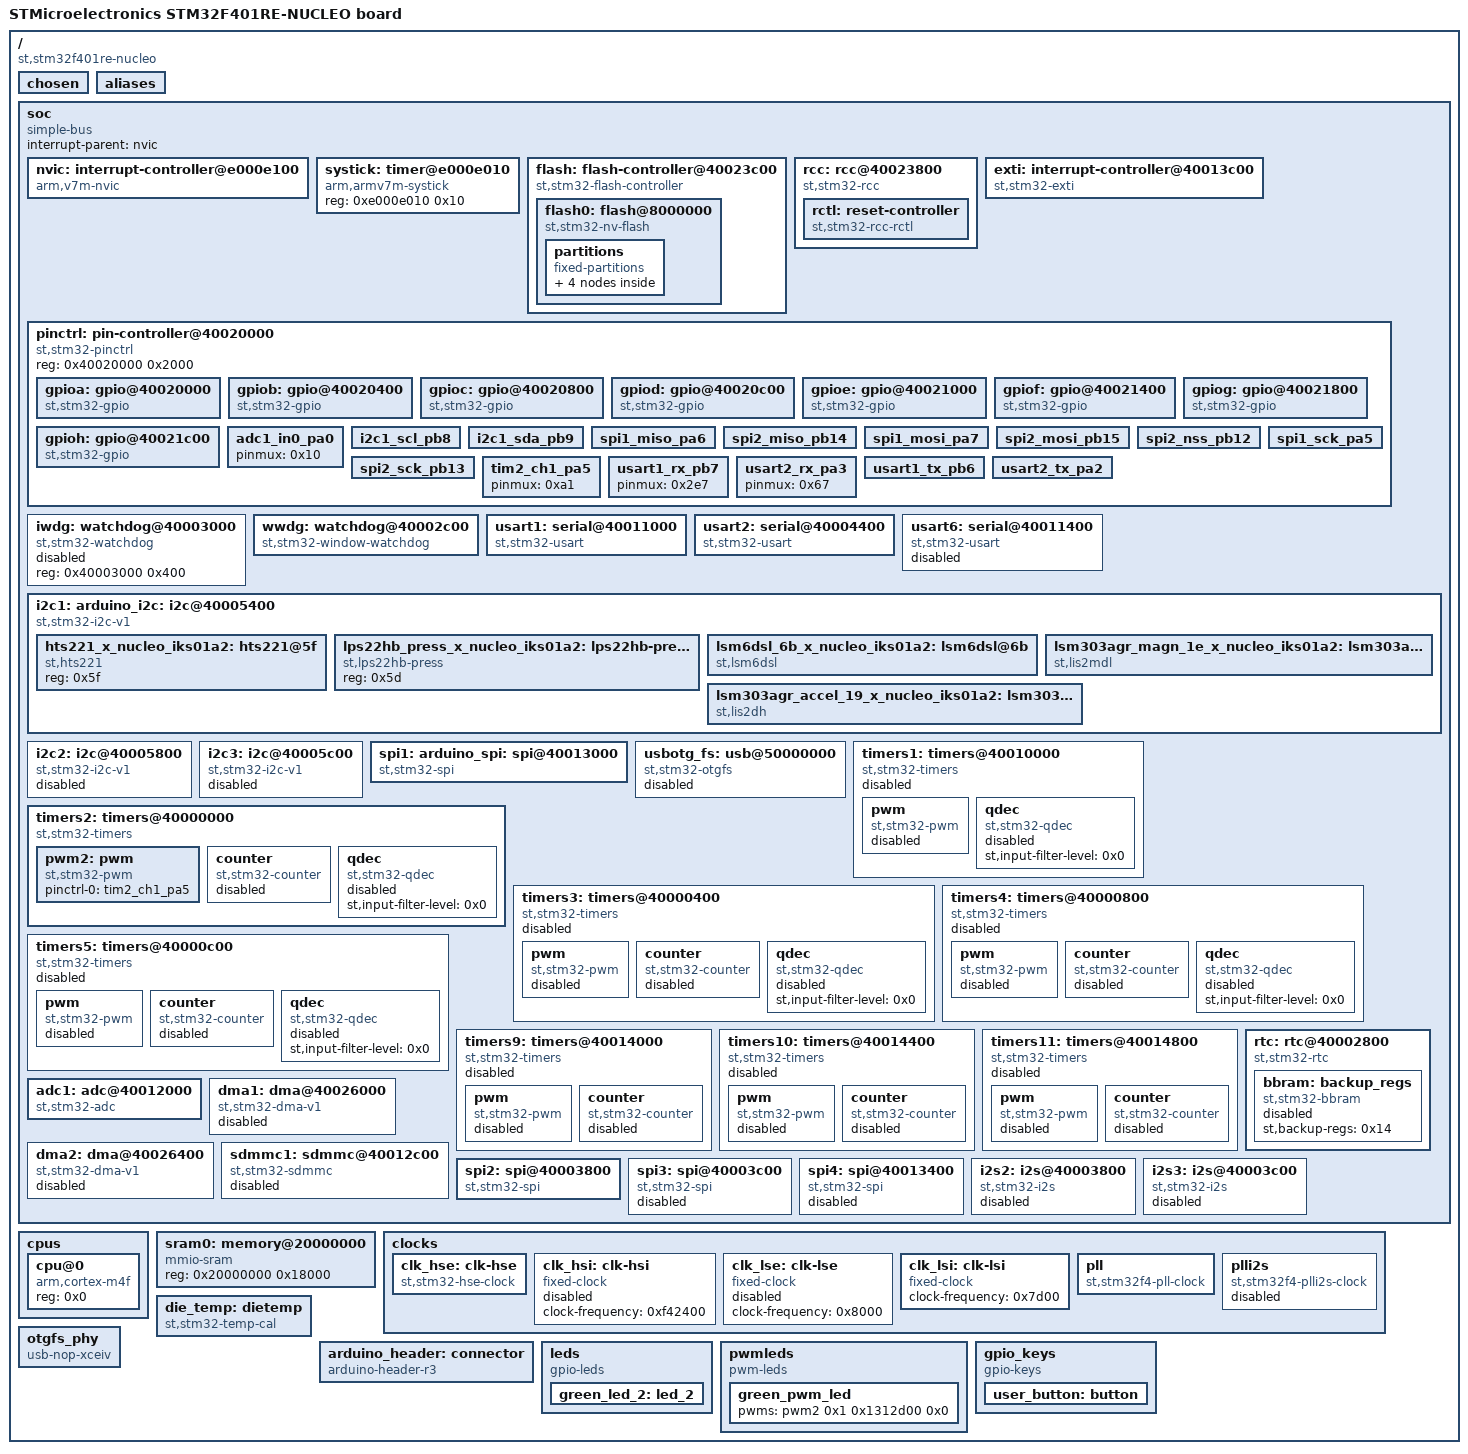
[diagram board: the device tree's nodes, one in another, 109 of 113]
/dts-v1/;

/ {
	#address-cells = < 0x1 >;
	#size-cells = < 0x1 >;
	model = "STMicroelectronics STM32F401RE-NUCLEO board";
	compatible = "st,stm32f401re-nucleo";
	chosen {
		zephyr,flash-controller = &flash;
		zephyr,console = &usart2;
		zephyr,shell-uart = &usart2;
		zephyr,sram = &sram0;
		zephyr,flash = &flash0;
		zephyr,code-partition = &slot0_partition;
	};
	aliases {
		led0 = &green_led_2;
		sw0 = &user_button;
		pwm-led0 = &green_pwm_led;
		watchdog0 = &wwdg;
		magn0 = &lsm303agr_magn_1e_x_nucleo_iks01a2;
		accel0 = &lsm303agr_accel_19_x_nucleo_iks01a2;
		accel1 = &lsm6dsl_6b_x_nucleo_iks01a2;
	};
	soc {
		#address-cells = < 0x1 >;
		#size-cells = < 0x1 >;
		compatible = "simple-bus";
		interrupt-parent = < &nvic >;
		ranges;
		nvic: interrupt-controller@e000e100 {
			#address-cells = < 0x1 >;
			compatible = "arm,v7m-nvic";
			reg = < 0xe000e100 0xc00 >;
			interrupt-controller;
			#interrupt-cells = < 0x2 >;
			arm,num-irq-priority-bits = < 0x4 >;
			phandle = < 0x1 >;
		};
		systick: timer@e000e010 {
			compatible = "arm,armv7m-systick";
			reg = < 0xe000e010 0x10 >;
		};
		flash: flash-controller@40023c00 {
			compatible = "st,stm32-flash-controller", "st,stm32f4-flash-controller";
			reg = < 0x40023c00 0x400 >;
			interrupts = < 0x4 0x0 >;
			#address-cells = < 0x1 >;
			#size-cells = < 0x1 >;
			flash0: flash@8000000 {
				compatible = "st,stm32-nv-flash", "soc-nv-flash";
				write-block-size = < 0x1 >;
				max-erase-time = < 0xfa0 >;
				reg = < 0x8000000 0x80000 >;
				partitions {
					compatible = "fixed-partitions";
					#address-cells = < 0x1 >;
					#size-cells = < 0x1 >;
					boot_partition: partition@0 {
						label = "mcuboot";
						reg = < 0x0 0x10000 >;
						read-only;
					};
					slot0_partition: partition@20000 {
						label = "image-0";
						reg = < 0x20000 0x20000 >;
					};
					slot1_partition: partition@40000 {
						label = "image-1";
						reg = < 0x40000 0x20000 >;
					};
					scratch_partition: partition@60000 {
						label = "image-scratch";
						reg = < 0x60000 0x20000 >;
					};
				};
			};
		};
		rcc: rcc@40023800 {
			compatible = "st,stm32-rcc";
			#clock-cells = < 0x2 >;
			reg = < 0x40023800 0x400 >;
			clocks = < &pll >;
			clock-frequency = < 0x501bd00 >;
			ahb-prescaler = < 0x1 >;
			apb1-prescaler = < 0x2 >;
			apb2-prescaler = < 0x1 >;
			phandle = < 0x3 >;
			rctl: reset-controller {
				compatible = "st,stm32-rcc-rctl";
				#reset-cells = < 0x1 >;
				phandle = < 0x4 >;
			};
		};
		exti: interrupt-controller@40013c00 {
			compatible = "st,stm32-exti";
			interrupt-controller;
			#interrupt-cells = < 0x1 >;
			reg = < 0x40013c00 0x400 >;
			num-lines = < 0x10 >;
			interrupts = < 0x6 0x0 >, < 0x7 0x0 >, < 0x8 0x0 >, < 0x9 0x0 >, < 0xa 0x0 >, < 0x17 0x0 >, < 0x28 0x0 >;
			interrupt-names = "line0", "line1", "line2", "line3", "line4", "line5-9", "line10-15";
			line-ranges = < 0x0 0x1 >, < 0x1 0x1 >, < 0x2 0x1 >, < 0x3 0x1 >, < 0x4 0x1 >, < 0x5 0x5 >, < 0xa 0x6 >;
		};
		pinctrl: pin-controller@40020000 {
			compatible = "st,stm32-pinctrl";
			#address-cells = < 0x1 >;
			#size-cells = < 0x1 >;
			reg = < 0x40020000 0x2000 >;
			gpioa: gpio@40020000 {
				compatible = "st,stm32-gpio";
				gpio-controller;
				#gpio-cells = < 0x2 >;
				reg = < 0x40020000 0x400 >;
				clocks = < &rcc 0x30 0x1 >;
				phandle = < 0x1a >;
			};
			gpiob: gpio@40020400 {
				compatible = "st,stm32-gpio";
				gpio-controller;
				#gpio-cells = < 0x2 >;
				reg = < 0x40020400 0x400 >;
				clocks = < &rcc 0x30 0x2 >;
				phandle = < 0xf >;
			};
			gpioc: gpio@40020800 {
				compatible = "st,stm32-gpio";
				gpio-controller;
				#gpio-cells = < 0x2 >;
				reg = < 0x40020800 0x400 >;
				clocks = < &rcc 0x30 0x4 >;
				phandle = < 0x1b >;
			};
			gpiod: gpio@40020c00 {
				compatible = "st,stm32-gpio";
				gpio-controller;
				#gpio-cells = < 0x2 >;
				reg = < 0x40020c00 0x400 >;
				clocks = < &rcc 0x30 0x8 >;
			};
			gpioe: gpio@40021000 {
				compatible = "st,stm32-gpio";
				gpio-controller;
				#gpio-cells = < 0x2 >;
				reg = < 0x40021000 0x400 >;
				clocks = < &rcc 0x30 0x10 >;
			};
			gpiof: gpio@40021400 {
				compatible = "st,stm32-gpio";
				gpio-controller;
				#gpio-cells = < 0x2 >;
				reg = < 0x40021400 0x400 >;
				clocks = < &rcc 0x30 0x20 >;
			};
			gpiog: gpio@40021800 {
				compatible = "st,stm32-gpio";
				gpio-controller;
				#gpio-cells = < 0x2 >;
				reg = < 0x40021800 0x400 >;
				clocks = < &rcc 0x30 0x40 >;
			};
			gpioh: gpio@40021c00 {
				compatible = "st,stm32-gpio";
				gpio-controller;
				#gpio-cells = < 0x2 >;
				reg = < 0x40021c00 0x400 >;
				clocks = < &rcc 0x30 0x80 >;
			};
			adc1_in0_pa0: adc1_in0_pa0 {
				pinmux = < 0x10 >;
				phandle = < 0x12 >;
			};
			i2c1_scl_pb8: i2c1_scl_pb8 {
				pinmux = < 0x304 >;
				bias-pull-up;
				drive-open-drain;
				phandle = < 0x9 >;
			};
			i2c1_sda_pb9: i2c1_sda_pb9 {
				pinmux = < 0x324 >;
				bias-pull-up;
				drive-open-drain;
				phandle = < 0xa >;
			};
			spi1_miso_pa6: spi1_miso_pa6 {
				pinmux = < 0xc5 >;
				bias-pull-down;
				phandle = < 0xd >;
			};
			spi2_miso_pb14: spi2_miso_pb14 {
				pinmux = < 0x3c5 >;
				bias-pull-down;
				phandle = < 0x15 >;
			};
			spi1_mosi_pa7: spi1_mosi_pa7 {
				pinmux = < 0xe5 >;
				bias-pull-down;
				phandle = < 0xe >;
			};
			spi2_mosi_pb15: spi2_mosi_pb15 {
				pinmux = < 0x3e5 >;
				bias-pull-down;
				phandle = < 0x16 >;
			};
			spi2_nss_pb12: spi2_nss_pb12 {
				pinmux = < 0x385 >;
				bias-pull-up;
				phandle = < 0x13 >;
			};
			spi1_sck_pa5: spi1_sck_pa5 {
				pinmux = < 0xa5 >;
				bias-pull-down;
				slew-rate = "very-high-speed";
				phandle = < 0xc >;
			};
			spi2_sck_pb13: spi2_sck_pb13 {
				pinmux = < 0x3a5 >;
				bias-pull-down;
				slew-rate = "very-high-speed";
				phandle = < 0x14 >;
			};
			tim2_ch1_pa5: tim2_ch1_pa5 {
				pinmux = < 0xa1 >;
				phandle = < 0x11 >;
			};
			usart1_rx_pb7: usart1_rx_pb7 {
				pinmux = < 0x2e7 >;
				phandle = < 0x6 >;
			};
			usart2_rx_pa3: usart2_rx_pa3 {
				pinmux = < 0x67 >;
				phandle = < 0x8 >;
			};
			usart1_tx_pb6: usart1_tx_pb6 {
				pinmux = < 0x2c7 >;
				bias-pull-up;
				phandle = < 0x5 >;
			};
			usart2_tx_pa2: usart2_tx_pa2 {
				pinmux = < 0x47 >;
				bias-pull-up;
				phandle = < 0x7 >;
			};
		};
		iwdg: watchdog@40003000 {
			compatible = "st,stm32-watchdog";
			reg = < 0x40003000 0x400 >;
			status = "disabled";
		};
		wwdg: watchdog@40002c00 {
			compatible = "st,stm32-window-watchdog";
			reg = < 0x40002c00 0x400 >;
			clocks = < &rcc 0x40 0x800 >;
			interrupts = < 0x0 0x7 >;
			status = "okay";
		};
		usart1: serial@40011000 {
			compatible = "st,stm32-usart", "st,stm32-uart";
			reg = < 0x40011000 0x400 >;
			clocks = < &rcc 0x44 0x10 >;
			resets = < &rctl 0x484 >;
			interrupts = < 0x25 0x0 >;
			status = "okay";
			pinctrl-0 = < &usart1_tx_pb6 &usart1_rx_pb7 >;
			pinctrl-names = "default";
			current-speed = < 0x1c200 >;
		};
		usart2: serial@40004400 {
			compatible = "st,stm32-usart", "st,stm32-uart";
			reg = < 0x40004400 0x400 >;
			clocks = < &rcc 0x40 0x20000 >;
			resets = < &rctl 0x411 >;
			interrupts = < 0x26 0x0 >;
			status = "okay";
			pinctrl-0 = < &usart2_tx_pa2 &usart2_rx_pa3 >;
			pinctrl-names = "default";
			current-speed = < 0x1c200 >;
		};
		usart6: serial@40011400 {
			compatible = "st,stm32-usart", "st,stm32-uart";
			reg = < 0x40011400 0x400 >;
			clocks = < &rcc 0x44 0x20 >;
			resets = < &rctl 0x485 >;
			interrupts = < 0x47 0x0 >;
			status = "disabled";
		};
		i2c1: arduino_i2c: i2c@40005400 {
			compatible = "st,stm32-i2c-v1";
			clock-frequency = < 0x61a80 >;
			#address-cells = < 0x1 >;
			#size-cells = < 0x0 >;
			reg = < 0x40005400 0x400 >;
			clocks = < &rcc 0x40 0x200000 >;
			interrupts = < 0x1f 0x0 >, < 0x20 0x0 >;
			interrupt-names = "event", "error";
			status = "okay";
			pinctrl-0 = < &i2c1_scl_pb8 &i2c1_sda_pb9 >;
			pinctrl-names = "default";
			hts221_x_nucleo_iks01a2: hts221@5f {
				compatible = "st,hts221";
				reg = < 0x5f >;
			};
			lps22hb_press_x_nucleo_iks01a2: lps22hb-press@5d {
				compatible = "st,lps22hb-press";
				reg = < 0x5d >;
			};
			lsm6dsl_6b_x_nucleo_iks01a2: lsm6dsl@6b {
				compatible = "st,lsm6dsl";
				reg = < 0x6b >;
				irq-gpios = < &arduino_header 0xa 0x0 >;
			};
			lsm303agr_magn_1e_x_nucleo_iks01a2: lsm303agr-magn@1e {
				compatible = "st,lis2mdl", "st,lsm303agr-magn";
				reg = < 0x1e >;
				irq-gpios = < &arduino_header 0x3 0x0 >;
			};
			lsm303agr_accel_19_x_nucleo_iks01a2: lsm303agr-accel@19 {
				compatible = "st,lis2dh", "st,lsm303agr-accel";
				reg = < 0x19 >;
				irq-gpios = < &arduino_header 0x3 0x0 >;
			};
		};
		i2c2: i2c@40005800 {
			compatible = "st,stm32-i2c-v1";
			clock-frequency = < 0x186a0 >;
			#address-cells = < 0x1 >;
			#size-cells = < 0x0 >;
			reg = < 0x40005800 0x400 >;
			clocks = < &rcc 0x40 0x400000 >;
			interrupts = < 0x21 0x0 >, < 0x22 0x0 >;
			interrupt-names = "event", "error";
			status = "disabled";
		};
		i2c3: i2c@40005c00 {
			compatible = "st,stm32-i2c-v1";
			clock-frequency = < 0x186a0 >;
			#address-cells = < 0x1 >;
			#size-cells = < 0x0 >;
			reg = < 0x40005c00 0x400 >;
			clocks = < &rcc 0x40 0x800000 >;
			interrupts = < 0x48 0x0 >, < 0x49 0x0 >;
			interrupt-names = "event", "error";
			status = "disabled";
		};
		spi1: arduino_spi: spi@40013000 {
			compatible = "st,stm32-spi";
			#address-cells = < 0x1 >;
			#size-cells = < 0x0 >;
			reg = < 0x40013000 0x400 >;
			clocks = < &rcc 0x44 0x1000 >;
			interrupts = < 0x23 0x5 >;
			status = "okay";
			pinctrl-0 = < &spi1_sck_pa5 &spi1_miso_pa6 &spi1_mosi_pa7 >;
			pinctrl-names = "default";
			cs-gpios = < &gpiob 0x6 0x11 >;
		};
		usbotg_fs: usb@50000000 {
			compatible = "st,stm32-otgfs";
			reg = < 0x50000000 0x40000 >;
			interrupts = < 0x43 0x0 >;
			interrupt-names = "otgfs";
			num-bidir-endpoints = < 0x4 >;
			ram-size = < 0x500 >;
			maximum-speed = "full-speed";
			phys = < &otgfs_phy >;
			clocks = < &rcc 0x34 0x80 >, < &rcc 0x2 0xff >;
			status = "disabled";
		};
		timers1: timers@40010000 {
			compatible = "st,stm32-timers";
			reg = < 0x40010000 0x400 >;
			clocks = < &rcc 0x44 0x1 >;
			resets = < &rctl 0x480 >;
			interrupts = < 0x18 0x0 >, < 0x19 0x0 >, < 0x1a 0x0 >, < 0x1b 0x0 >;
			interrupt-names = "brk", "up", "trgcom", "cc";
			st,prescaler = < 0x0 >;
			status = "disabled";
			pwm {
				compatible = "st,stm32-pwm";
				status = "disabled";
				#pwm-cells = < 0x3 >;
			};
			qdec {
				compatible = "st,stm32-qdec";
				status = "disabled";
				st,input-filter-level = < 0x0 >;
			};
		};
		timers2: timers@40000000 {
			compatible = "st,stm32-timers";
			reg = < 0x40000000 0x400 >;
			clocks = < &rcc 0x40 0x1 >;
			resets = < &rctl 0x400 >;
			interrupts = < 0x1c 0x0 >;
			interrupt-names = "global";
			st,prescaler = < 0x0 >;
			status = "okay";
			pwm2: pwm {
				compatible = "st,stm32-pwm";
				status = "okay";
				#pwm-cells = < 0x3 >;
				pinctrl-0 = < &tim2_ch1_pa5 >;
				pinctrl-names = "default";
				phandle = < 0x1c >;
			};
			counter {
				compatible = "st,stm32-counter";
				status = "disabled";
			};
			qdec {
				compatible = "st,stm32-qdec";
				status = "disabled";
				st,input-filter-level = < 0x0 >;
			};
		};
		timers3: timers@40000400 {
			compatible = "st,stm32-timers";
			reg = < 0x40000400 0x400 >;
			clocks = < &rcc 0x40 0x2 >;
			resets = < &rctl 0x401 >;
			interrupts = < 0x1d 0x0 >;
			interrupt-names = "global";
			st,prescaler = < 0x0 >;
			status = "disabled";
			pwm {
				compatible = "st,stm32-pwm";
				status = "disabled";
				#pwm-cells = < 0x3 >;
			};
			counter {
				compatible = "st,stm32-counter";
				status = "disabled";
			};
			qdec {
				compatible = "st,stm32-qdec";
				status = "disabled";
				st,input-filter-level = < 0x0 >;
			};
		};
		timers4: timers@40000800 {
			compatible = "st,stm32-timers";
			reg = < 0x40000800 0x400 >;
			clocks = < &rcc 0x40 0x4 >;
			resets = < &rctl 0x402 >;
			interrupts = < 0x1e 0x0 >;
			interrupt-names = "global";
			st,prescaler = < 0x0 >;
			status = "disabled";
			pwm {
				compatible = "st,stm32-pwm";
				status = "disabled";
				#pwm-cells = < 0x3 >;
			};
			counter {
				compatible = "st,stm32-counter";
				status = "disabled";
			};
			qdec {
				compatible = "st,stm32-qdec";
				status = "disabled";
				st,input-filter-level = < 0x0 >;
			};
		};
		timers5: timers@40000c00 {
			compatible = "st,stm32-timers";
			reg = < 0x40000c00 0x400 >;
			clocks = < &rcc 0x40 0x8 >;
			resets = < &rctl 0x403 >;
			interrupts = < 0x32 0x0 >;
			interrupt-names = "global";
			st,prescaler = < 0x0 >;
			status = "disabled";
			pwm {
				compatible = "st,stm32-pwm";
				status = "disabled";
				#pwm-cells = < 0x3 >;
			};
			counter {
				compatible = "st,stm32-counter";
				status = "disabled";
			};
			qdec {
				compatible = "st,stm32-qdec";
				status = "disabled";
				st,input-filter-level = < 0x0 >;
			};
		};
		timers9: timers@40014000 {
			compatible = "st,stm32-timers";
			reg = < 0x40014000 0x400 >;
			clocks = < &rcc 0x44 0x10000 >;
			resets = < &rctl 0x490 >;
			interrupts = < 0x18 0x0 >;
			interrupt-names = "global";
			st,prescaler = < 0x0 >;
			status = "disabled";
			pwm {
				compatible = "st,stm32-pwm";
				status = "disabled";
				#pwm-cells = < 0x3 >;
			};
			counter {
				compatible = "st,stm32-counter";
				status = "disabled";
			};
		};
		timers10: timers@40014400 {
			compatible = "st,stm32-timers";
			reg = < 0x40014400 0x400 >;
			clocks = < &rcc 0x44 0x20000 >;
			resets = < &rctl 0x491 >;
			interrupts = < 0x19 0x0 >;
			interrupt-names = "global";
			st,prescaler = < 0x0 >;
			status = "disabled";
			pwm {
				compatible = "st,stm32-pwm";
				status = "disabled";
				#pwm-cells = < 0x3 >;
			};
			counter {
				compatible = "st,stm32-counter";
				status = "disabled";
			};
		};
		timers11: timers@40014800 {
			compatible = "st,stm32-timers";
			reg = < 0x40014800 0x400 >;
			clocks = < &rcc 0x44 0x40000 >;
			resets = < &rctl 0x492 >;
			interrupts = < 0x1a 0x0 >;
			interrupt-names = "global";
			st,prescaler = < 0x0 >;
			status = "disabled";
			pwm {
				compatible = "st,stm32-pwm";
				status = "disabled";
				#pwm-cells = < 0x3 >;
			};
			counter {
				compatible = "st,stm32-counter";
				status = "disabled";
			};
		};
		rtc: rtc@40002800 {
			compatible = "st,stm32-rtc";
			reg = < 0x40002800 0x400 >;
			interrupts = < 0x29 0x0 >;
			clocks = < &rcc 0x40 0x10000000 >, < &rcc 0x5 0x26870 >;
			prescaler = < 0x8000 >;
			status = "okay";
			bbram: backup_regs {
				compatible = "st,stm32-bbram";
				st,backup-regs = < 0x14 >;
				status = "disabled";
			};
		};
		adc1: adc@40012000 {
			compatible = "st,stm32-adc";
			reg = < 0x40012000 0x400 >;
			clocks = < &rcc 0x44 0x100 >;
			interrupts = < 0x12 0x0 >;
			status = "okay";
			#io-channel-cells = < 0x1 >;
			temp-channel = < 0x12 >;
			vref-channel = < 0x11 >;
			pinctrl-0 = < &adc1_in0_pa0 >;
			pinctrl-names = "default";
			phandle = < 0x19 >;
		};
		dma1: dma@40026000 {
			compatible = "st,stm32-dma-v1";
			#dma-cells = < 0x4 >;
			reg = < 0x40026000 0x400 >;
			interrupts = < 0xb 0x0 0xc 0x0 0xd 0x0 0xe 0x0 0xf 0x0 0x10 0x0 0x11 0x0 0x2f 0x0 >;
			clocks = < &rcc 0x30 0x200000 >;
			status = "disabled";
			phandle = < 0x17 >;
		};
		dma2: dma@40026400 {
			compatible = "st,stm32-dma-v1";
			#dma-cells = < 0x4 >;
			reg = < 0x40026400 0x400 >;
			interrupts = < 0x38 0x0 0x39 0x0 0x3a 0x0 0x3b 0x0 0x3c 0x0 0x44 0x0 0x45 0x0 0x46 0x0 >;
			clocks = < &rcc 0x30 0x400000 >;
			st,mem2mem;
			status = "disabled";
		};
		sdmmc1: sdmmc@40012c00 {
			compatible = "st,stm32-sdmmc";
			reg = < 0x40012c00 0x400 >;
			clocks = < &rcc 0x44 0x800 >, < &rcc 0x2 0xff >;
			resets = < &rctl 0x48b >;
			interrupts = < 0x31 0x0 >;
			status = "disabled";
		};
		spi2: spi@40003800 {
			compatible = "st,stm32-spi";
			#address-cells = < 0x1 >;
			#size-cells = < 0x0 >;
			reg = < 0x40003800 0x400 >;
			clocks = < &rcc 0x40 0x4000 >;
			interrupts = < 0x24 0x5 >;
			status = "okay";
			pinctrl-0 = < &spi2_nss_pb12 &spi2_sck_pb13 &spi2_miso_pb14 &spi2_mosi_pb15 >;
			pinctrl-names = "default";
		};
		spi3: spi@40003c00 {
			compatible = "st,stm32-spi";
			#address-cells = < 0x1 >;
			#size-cells = < 0x0 >;
			reg = < 0x40003c00 0x400 >;
			clocks = < &rcc 0x40 0x8000 >;
			interrupts = < 0x33 0x5 >;
			status = "disabled";
		};
		spi4: spi@40013400 {
			compatible = "st,stm32-spi";
			#address-cells = < 0x1 >;
			#size-cells = < 0x0 >;
			reg = < 0x40013400 0x400 >;
			clocks = < &rcc 0x44 0x2000 >;
			interrupts = < 0x54 0x5 >;
			status = "disabled";
		};
		i2s2: i2s@40003800 {
			compatible = "st,stm32-i2s";
			#address-cells = < 0x1 >;
			#size-cells = < 0x0 >;
			reg = < 0x40003800 0x400 >;
			clocks = < &rcc 0x40 0x4000 >;
			interrupts = < 0x24 0x5 >;
			dmas = < &dma1 0x4 0x0 0x400 0x3 &dma1 0x3 0x0 0x400 0x3 >;
			dma-names = "tx", "rx";
			status = "disabled";
		};
		i2s3: i2s@40003c00 {
			compatible = "st,stm32-i2s";
			#address-cells = < 0x1 >;
			#size-cells = < 0x0 >;
			reg = < 0x40003c00 0x400 >;
			clocks = < &rcc 0x40 0x8000 >;
			interrupts = < 0x33 0x5 >;
			dmas = < &dma1 0x5 0x0 0x400 0x3 &dma1 0x0 0x0 0x400 0x3 >;
			dma-names = "tx", "rx";
			status = "disabled";
		};
	};
	cpus {
		#address-cells = < 0x1 >;
		#size-cells = < 0x0 >;
		cpu@0 {
			device_type = "cpu";
			compatible = "arm,cortex-m4f";
			reg = < 0x0 >;
		};
	};
	sram0: memory@20000000 {
		compatible = "mmio-sram";
		reg = < 0x20000000 0x18000 >;
	};
	clocks {
		clk_hse: clk-hse {
			#clock-cells = < 0x0 >;
			compatible = "st,stm32-hse-clock";
			status = "okay";
			hse-bypass;
			clock-frequency = < 0x7a1200 >;
			phandle = < 0x18 >;
		};
		clk_hsi: clk-hsi {
			#clock-cells = < 0x0 >;
			compatible = "fixed-clock";
			clock-frequency = < 0xf42400 >;
			status = "disabled";
		};
		clk_lse: clk-lse {
			#clock-cells = < 0x0 >;
			compatible = "fixed-clock";
			clock-frequency = < 0x8000 >;
			status = "disabled";
		};
		clk_lsi: clk-lsi {
			#clock-cells = < 0x0 >;
			compatible = "fixed-clock";
			clock-frequency = < 0x7d00 >;
			status = "okay";
		};
		pll: pll {
			#clock-cells = < 0x0 >;
			compatible = "st,stm32f4-pll-clock";
			status = "okay";
			div-m = < 0x8 >;
			mul-n = < 0x150 >;
			div-p = < 0x4 >;
			div-q = < 0x7 >;
			clocks = < &clk_hse >;
			phandle = < 0x2 >;
		};
		plli2s: plli2s {
			#clock-cells = < 0x0 >;
			compatible = "st,stm32f4-plli2s-clock";
			status = "disabled";
		};
	};
	die_temp: dietemp {
		compatible = "st,stm32-temp-cal";
		ts-cal1-addr = < 0x1fff7a2c >;
		ts-cal2-addr = < 0x1fff7a2e >;
		ts-cal1-temp = < 0x1e >;
		ts-cal2-temp = < 0x6e >;
		ts-cal-vrefanalog = < 0xce4 >;
		io-channels = < &adc1 0x10 >;
		status = "okay";
	};
	otgfs_phy: otgfs_phy {
		compatible = "usb-nop-xceiv";
		#phy-cells = < 0x0 >;
		phandle = < 0x10 >;
	};
	arduino_header: connector {
		compatible = "arduino-header-r3";
		#gpio-cells = < 0x2 >;
		gpio-map-mask = < 0xffffffff 0xffffffc0 >;
		gpio-map-pass-thru = < 0x0 0x3f >;
		gpio-map = < 0x0 0x0 &gpioa 0x0 0x0 >, < 0x1 0x0 &gpioa 0x1 0x0 >, < 0x2 0x0 &gpioa 0x4 0x0 >, < 0x3 0x0 &gpiob 0x0 0x0 >, < 0x4 0x0 &gpioc 0x1 0x0 >, < 0x5 0x0 &gpioc 0x0 0x0 >, < 0x6 0x0 &gpioa 0x3 0x0 >, < 0x7 0x0 &gpioa 0x2 0x0 >, < 0x8 0x0 &gpioa 0xa 0x0 >, < 0x9 0x0 &gpiob 0x3 0x0 >, < 0xa 0x0 &gpiob 0x5 0x0 >, < 0xb 0x0 &gpiob 0x4 0x0 >, < 0xc 0x0 &gpiob 0xa 0x0 >, < 0xd 0x0 &gpioa 0x8 0x0 >, < 0xe 0x0 &gpioa 0x9 0x0 >, < 0xf 0x0 &gpioc 0x7 0x0 >, < 0x10 0x0 &gpiob 0x6 0x0 >, < 0x11 0x0 &gpioa 0x7 0x0 >, < 0x12 0x0 &gpioa 0x6 0x0 >, < 0x13 0x0 &gpioa 0x5 0x0 >, < 0x14 0x0 &gpiob 0x9 0x0 >, < 0x15 0x0 &gpiob 0x8 0x0 >;
		phandle = < 0xb >;
	};
	leds {
		compatible = "gpio-leds";
		green_led_2: led_2 {
			gpios = < &gpioa 0x5 0x0 >;
			label = "User LD2";
		};
	};
	pwmleds {
		compatible = "pwm-leds";
		green_pwm_led: green_pwm_led {
			pwms = < &pwm2 0x1 0x1312d00 0x0 >;
		};
	};
	gpio_keys {
		compatible = "gpio-keys";
		user_button: button {
			label = "User";
			gpios = < &gpioc 0xd 0x1 >;
		};
	};
};
